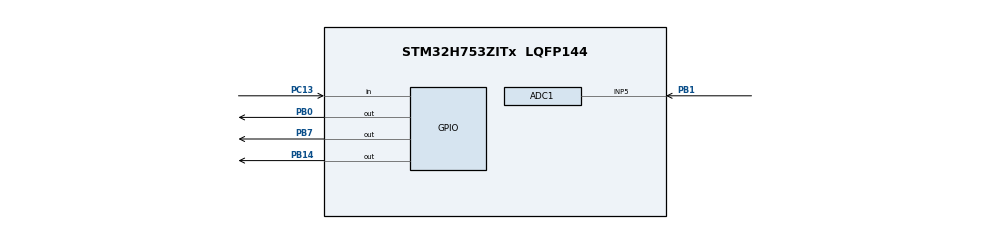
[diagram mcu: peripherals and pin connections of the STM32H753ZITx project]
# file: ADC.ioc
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ADC1.Channel-1\#ChannelRegularConversion=ADC_CHANNEL_5
ADC1.ContinuousConvMode=ENABLE
ADC1.NbrOfConversionFlag=1
ADC1.OffsetNumber-1\#ChannelRegularConversion=ADC_OFFSET_NONE
ADC1.OffsetSignedSaturation-1\#ChannelRegularConversion=DISABLE
ADC1.Rank-1\#ChannelRegularConversion=1
ADC1.SamplingTime-1\#ChannelRegularConversion=ADC_SAMPLETIME_1CYCLE_5
ADC1.master=1
CORTEX_M7.CPU_DCache=Disabled
CORTEX_M7.CPU_ICache=Disabled
CORTEX_M7.MPU_Control=__NULL
CORTEX_M7.default_mode_Activation=1
Mcu.Family=STM32H7
Mcu.Name=STM32H753ZITx
Mcu.Package=LQFP144
NUCLEO-H753ZI.BUTTON=1
NUCLEO-H753ZI.LD1=true
NUCLEO-H753ZI.LD2=true
NUCLEO-H753ZI.LD3=true
NUCLEO-H753ZI.VCP=true
NVIC.ADC_IRQn=true\:0\:0\:false\:false\:true\:true\:true\:true
NVIC.EXTI15_10_IRQn=true\:0\:0\:false\:false\:true\:false\:true\:true
NVIC.PriorityGroup=NVIC_PRIORITYGROUP_4
PB0.Signal=GPIO_Output
PB1.Signal=ADCx_INP5
PB14.Signal=GPIO_Output
PB7.Signal=GPIO_Output
PC13.Signal=GPIO_Input
PD8.Signal=USART3_TX
PD9.Signal=USART3_RX
ProjectManager.HeapSize=0x200
ProjectManager.StackSize=0x400
ProjectManager.TargetToolchain=STM32CubeIDE
RCC.ADCFreq_Value=80000000
RCC.APB1Freq_Value=64000000
RCC.APB2Freq_Value=64000000
RCC.APB3Freq_Value=64000000
RCC.APB4Freq_Value=64000000
RCC.CortexFreq_Value=64000000
RCC.DIVM1=1
RCC.DIVM2=4
RCC.DIVN1=24
RCC.DIVN2=10
RCC.DIVQ1=4
RCC.HCLKFreq_Value=64000000
RCC.HSE_VALUE=8000000
RCC.PLL2FRACN=0
RCC.PLLFRACN=0
RCC.PWR_Regulator_Voltage_Scale=PWR_REGULATOR_VOLTAGE_SCALE2
RCC.SYSCLKFreq_VALUE=64000000
RCC.USBFreq_Value=384000000
SH.ADCx_INP5.0=ADC1_INP5,IN5-Single-Ended
VP_MEMORYMAP_VS_MEMORYMAP.Mode=CurAppReg
VP_NUCLEO-H753ZI_VS_BSP_COMMON.Mode=COMMON
board=NUCLEO-H753ZI

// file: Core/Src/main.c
/* USER CODE BEGIN Header */
/**
  ******************************************************************************
  * @file           : main.c
  * @brief          : Main program body
  ******************************************************************************
  * @attention
  *
  * Copyright (c) 2026 STMicroelectronics.
  * All rights reserved.
  *
  * This software is licensed under terms that can be found in the LICENSE file
  * in the root directory of this software component.
  * If no LICENSE file comes with this software, it is provided AS-IS.
  *
  ******************************************************************************
  */
/* USER CODE END Header */
#include "main.h"

COM_InitTypeDef BspCOMInit;
ADC_HandleTypeDef hadc1;

/* USER CODE BEGIN PV */
volatile uint32_t adc_value = 0;
volatile float voltage = 0.0f;
/* USER CODE END PV */

void SystemClock_Config(void);
static void MX_GPIO_Init(void);
static void MX_ADC1_Init(void);

int main(void)
{

  /* MCU Configuration--------------------------------------------------------*/

  /* Reset of all peripherals, Initializes the Flash interface and the Systick. */
  HAL_Init();

  /* Configure the system clock */
  SystemClock_Config();

  /* Initialize all configured peripherals */
  MX_GPIO_Init();
  MX_ADC1_Init();
  /* USER CODE BEGIN 2 */
  HAL_ADCEx_Calibration_Start(&hadc1, ADC_CALIB_OFFSET, ADC_SINGLE_ENDED);
  HAL_ADC_Start(&hadc1); // ADC modülünü çalıştırıyoruz
  /* USER CODE END 2 */

  /* Initialize leds */
  BSP_LED_Init(LED_GREEN);
  BSP_LED_Init(LED_BLUE);
  BSP_LED_Init(LED_RED);

  /* Initialize USER push-button, will be used to trigger an interrupt each time it's pressed.*/
  BSP_PB_Init(BUTTON_USER, BUTTON_MODE_EXTI);

  /* Initialize COM1 port (115200, 8 bits (7-bit data + 1 stop bit), no parity */
  BspCOMInit.BaudRate   = 115200;
  BspCOMInit.WordLength = COM_WORDLENGTH_8B;
  BspCOMInit.StopBits   = COM_STOPBITS_1;
  BspCOMInit.Parity     = COM_PARITY_NONE;
  BspCOMInit.HwFlowCtl  = COM_HWCONTROL_NONE;
  if (BSP_COM_Init(COM1, &BspCOMInit) != BSP_ERROR_NONE)
  {
    Error_Handler();
  }

  /* Infinite loop */
  /* USER CODE BEGIN WHILE */
  while (1)
  {
	  // ADC zaten arka planda ölçüyor, sadece verinin hazır olmasını bekliyoruz
	        if (HAL_ADC_PollForConversion(&hadc1, 1) == HAL_OK)
	        {
	            adc_value = HAL_ADC_GetValue(&hadc1);
	            voltage = ((float)adc_value * 3.3f) / 65535.0f;
	        }

	        HAL_Delay(100); // Canlı takip için 50ms (20Hz) çok idealdir
    /* USER CODE END WHILE */

  }
}

void SystemClock_Config(void)
{
  RCC_OscInitTypeDef RCC_OscInitStruct = {0};
  RCC_ClkInitTypeDef RCC_ClkInitStruct = {0};

  /** Supply configuration update enable
  */
  HAL_PWREx_ConfigSupply(PWR_LDO_SUPPLY);

  /** Configure the main internal regulator output voltage
  */
  __HAL_PWR_VOLTAGESCALING_CONFIG(PWR_REGULATOR_VOLTAGE_SCALE2);

  while(!__HAL_PWR_GET_FLAG(PWR_FLAG_VOSRDY)) {}

  /** Macro to configure the PLL clock source
  */
  __HAL_RCC_PLL_PLLSOURCE_CONFIG(RCC_PLLSOURCE_HSI);

  /** Initializes the RCC Oscillators according to the specified parameters
  * in the RCC_OscInitTypeDef structure.
  */
  RCC_OscInitStruct.OscillatorType = RCC_OSCILLATORTYPE_HSI;
  RCC_OscInitStruct.HSIState = RCC_HSI_DIV1;
  RCC_OscInitStruct.HSICalibrationValue = RCC_HSICALIBRATION_DEFAULT;
  RCC_OscInitStruct.PLL.PLLState = RCC_PLL_NONE;
  if (HAL_RCC_OscConfig(&RCC_OscInitStruct) != HAL_OK)
  {
    Error_Handler();
  }

  /** Initializes the CPU, AHB and APB buses clocks
  */
  RCC_ClkInitStruct.ClockType = RCC_CLOCKTYPE_HCLK|RCC_CLOCKTYPE_SYSCLK
                              |RCC_CLOCKTYPE_PCLK1|RCC_CLOCKTYPE_PCLK2
                              |RCC_CLOCKTYPE_D3PCLK1|RCC_CLOCKTYPE_D1PCLK1;
  RCC_ClkInitStruct.SYSCLKSource = RCC_SYSCLKSOURCE_HSI;
  RCC_ClkInitStruct.SYSCLKDivider = RCC_SYSCLK_DIV1;
  RCC_ClkInitStruct.AHBCLKDivider = RCC_HCLK_DIV1;
  RCC_ClkInitStruct.APB3CLKDivider = RCC_APB3_DIV1;
  RCC_ClkInitStruct.APB1CLKDivider = RCC_APB1_DIV1;
  RCC_ClkInitStruct.APB2CLKDivider = RCC_APB2_DIV1;
  RCC_ClkInitStruct.APB4CLKDivider = RCC_APB4_DIV1;

  if (HAL_RCC_ClockConfig(&RCC_ClkInitStruct, FLASH_LATENCY_1) != HAL_OK)
  {
    Error_Handler();
  }
}

static void MX_ADC1_Init(void)
{

  ADC_MultiModeTypeDef multimode = {0};
  ADC_ChannelConfTypeDef sConfig = {0};

  /** Common config
  */
  hadc1.Instance = ADC1;
  hadc1.Init.ClockPrescaler = ADC_CLOCK_ASYNC_DIV2;
  hadc1.Init.Resolution = ADC_RESOLUTION_16B;
  hadc1.Init.ScanConvMode = ADC_SCAN_DISABLE;
  hadc1.Init.EOCSelection = ADC_EOC_SINGLE_CONV;
  hadc1.Init.LowPowerAutoWait = DISABLE;
  hadc1.Init.ContinuousConvMode = ENABLE;
  hadc1.Init.NbrOfConversion = 1;
  hadc1.Init.DiscontinuousConvMode = DISABLE;
  hadc1.Init.ExternalTrigConv = ADC_SOFTWARE_START;
  hadc1.Init.ExternalTrigConvEdge = ADC_EXTERNALTRIGCONVEDGE_NONE;
  hadc1.Init.ConversionDataManagement = ADC_CONVERSIONDATA_DR;
  hadc1.Init.Overrun = ADC_OVR_DATA_PRESERVED;
  hadc1.Init.LeftBitShift = ADC_LEFTBITSHIFT_NONE;
  hadc1.Init.OversamplingMode = DISABLE;
  hadc1.Init.Oversampling.Ratio = 1;
  if (HAL_ADC_Init(&hadc1) != HAL_OK)
  {
    Error_Handler();
  }

  /** Configure the ADC multi-mode
  */
  multimode.Mode = ADC_MODE_INDEPENDENT;
  if (HAL_ADCEx_MultiModeConfigChannel(&hadc1, &multimode) != HAL_OK)
  {
    Error_Handler();
  }

  /** Configure Regular Channel
  */
  sConfig.Channel = ADC_CHANNEL_5;
  sConfig.Rank = ADC_REGULAR_RANK_1;
  sConfig.SamplingTime = ADC_SAMPLETIME_1CYCLE_5;
  sConfig.SingleDiff = ADC_SINGLE_ENDED;
  sConfig.OffsetNumber = ADC_OFFSET_NONE;
  sConfig.Offset = 0;
  sConfig.OffsetSignedSaturation = DISABLE;
  if (HAL_ADC_ConfigChannel(&hadc1, &sConfig) != HAL_OK)
  {
    Error_Handler();
  }

}

static void MX_GPIO_Init(void)
{

  /* GPIO Ports Clock Enable */
  __HAL_RCC_GPIOB_CLK_ENABLE();

}

void Error_Handler(void)
{
  __disable_irq();
  while (1)
  {
  }
}
